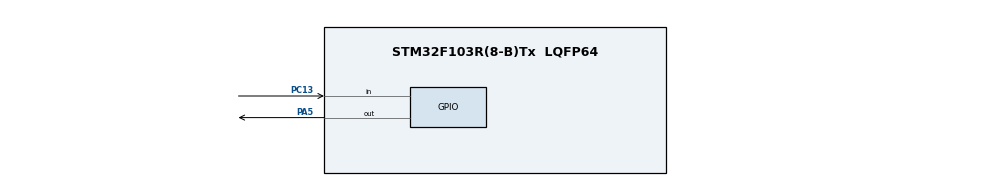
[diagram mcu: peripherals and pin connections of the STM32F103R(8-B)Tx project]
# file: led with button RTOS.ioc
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FREERTOS.Tasks01=defaultTask,24,128,StartDefaultTask,Default,NULL,Dynamic,NULL,NULL;led,24,128,ledTask02,Default,NULL,Dynamic,NULL,NULL
Mcu.Family=STM32F1
Mcu.Name=STM32F103R(8-B)Tx
Mcu.Package=LQFP64
NVIC.PriorityGroup=NVIC_PRIORITYGROUP_4
NVIC.TIM2_IRQn=true\:15\:0\:false\:false\:true\:false\:false\:true\:true
NVIC.TimeBase=TIM2_IRQn
NVIC.TimeBaseIP=TIM2
PA13.Mode=Serial_Wire
PA13.Signal=SYS_JTMS-SWDIO
PA14.Mode=Serial_Wire
PA14.Signal=SYS_JTCK-SWCLK
PA5.Signal=GPIO_Output
PC13-TAMPER-RTC.Signal=GPIO_Input
ProjectManager.HeapSize=0x200
ProjectManager.StackSize=0x400
ProjectManager.TargetToolchain=STM32CubeIDE
RCC.APB1Freq_Value=8000000
RCC.APB2Freq_Value=8000000
VP_FREERTOS_VS_CMSIS_V2.Mode=CMSIS_V2
VP_SYS_VS_tim2.Mode=TIM2
board=custom

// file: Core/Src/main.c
/* USER CODE BEGIN Header */
/**
  ******************************************************************************
  * @file           : main.c
  * @brief          : Main program body
  ******************************************************************************
  * @attention
  *
  * Copyright (c) 2026 STMicroelectronics.
  * All rights reserved.
  *
  * This software is licensed under terms that can be found in the LICENSE file
  * in the root directory of this software component.
  * If no LICENSE file comes with this software, it is provided AS-IS.
  *
  ******************************************************************************
  */
/* USER CODE END Header */
#include "main.h"
#include "cmsis_os.h"

/* Definitions for defaultTask */
osThreadId_t defaultTaskHandle;
const osThreadAttr_t defaultTask_attributes = {
  .name = "defaultTask",
  .stack_size = 128 * 4,
  .priority = (osPriority_t) osPriorityNormal,
};
/* Definitions for led */
osThreadId_t ledHandle;
const osThreadAttr_t led_attributes = {
  .name = "led",
  .stack_size = 128 * 4,
  .priority = (osPriority_t) osPriorityNormal,
};
/* USER CODE BEGIN PV */

volatile uint8_t buttonpress = 0;

/* USER CODE END PV */

void SystemClock_Config(void);
static void MX_GPIO_Init(void);
void StartDefaultTask(void *argument);
void ledTask02(void *argument);

int main(void)
{

  /* MCU Configuration--------------------------------------------------------*/

  /* Reset of all peripherals, Initializes the Flash interface and the Systick. */
  HAL_Init();

  /* Configure the system clock */
  SystemClock_Config();

  /* Initialize all configured peripherals */
  MX_GPIO_Init();

  /* Init scheduler */
  osKernelInitialize();

  /* Create the thread(s) */
  /* creation of defaultTask */
  defaultTaskHandle = osThreadNew(StartDefaultTask, NULL, &defaultTask_attributes);

  /* creation of led */
  ledHandle = osThreadNew(ledTask02, NULL, &led_attributes);

  /* Start scheduler */
  osKernelStart();

  /* We should never get here as control is now taken by the scheduler */

  /* Infinite loop */
  while (1)
  {

  }
}

void SystemClock_Config(void)
{
  RCC_OscInitTypeDef RCC_OscInitStruct = {0};
  RCC_ClkInitTypeDef RCC_ClkInitStruct = {0};

  /** Initializes the RCC Oscillators according to the specified parameters
  * in the RCC_OscInitTypeDef structure.
  */
  RCC_OscInitStruct.OscillatorType = RCC_OSCILLATORTYPE_HSI;
  RCC_OscInitStruct.HSIState = RCC_HSI_ON;
  RCC_OscInitStruct.HSICalibrationValue = RCC_HSICALIBRATION_DEFAULT;
  RCC_OscInitStruct.PLL.PLLState = RCC_PLL_NONE;
  if (HAL_RCC_OscConfig(&RCC_OscInitStruct) != HAL_OK)
  {
    Error_Handler();
  }

  /** Initializes the CPU, AHB and APB buses clocks
  */
  RCC_ClkInitStruct.ClockType = RCC_CLOCKTYPE_HCLK|RCC_CLOCKTYPE_SYSCLK
                              |RCC_CLOCKTYPE_PCLK1|RCC_CLOCKTYPE_PCLK2;
  RCC_ClkInitStruct.SYSCLKSource = RCC_SYSCLKSOURCE_HSI;
  RCC_ClkInitStruct.AHBCLKDivider = RCC_SYSCLK_DIV1;
  RCC_ClkInitStruct.APB1CLKDivider = RCC_HCLK_DIV1;
  RCC_ClkInitStruct.APB2CLKDivider = RCC_HCLK_DIV1;

  if (HAL_RCC_ClockConfig(&RCC_ClkInitStruct, FLASH_LATENCY_0) != HAL_OK)
  {
    Error_Handler();
  }
}

static void MX_GPIO_Init(void)
{
  GPIO_InitTypeDef GPIO_InitStruct = {0};

  /* GPIO Ports Clock Enable */
  __HAL_RCC_GPIOC_CLK_ENABLE();
  __HAL_RCC_GPIOA_CLK_ENABLE();

  /*Configure GPIO pin Output Level */
  HAL_GPIO_WritePin(GPIOA, GPIO_PIN_5, GPIO_PIN_RESET);

  /*Configure GPIO pin : PC13 */
  GPIO_InitStruct.Pin = GPIO_PIN_13;
  GPIO_InitStruct.Mode = GPIO_MODE_INPUT;
  GPIO_InitStruct.Pull = GPIO_NOPULL;
  HAL_GPIO_Init(GPIOC, &GPIO_InitStruct);

  /*Configure GPIO pin : PA5 */
  GPIO_InitStruct.Pin = GPIO_PIN_5;
  GPIO_InitStruct.Mode = GPIO_MODE_OUTPUT_PP;
  GPIO_InitStruct.Pull = GPIO_NOPULL;
  GPIO_InitStruct.Speed = GPIO_SPEED_FREQ_LOW;
  HAL_GPIO_Init(GPIOA, &GPIO_InitStruct);

}

void StartDefaultTask(void *argument)
{
  /* USER CODE BEGIN 5 */
  /* Infinite loop */
  for(;;)

	      {
	          if (HAL_GPIO_ReadPin(GPIOC, GPIO_PIN_13) == GPIO_PIN_RESET)
	          {

	        	   buttonpress = 1;
	          }
	          else
	       {

	         	  buttonpress = 0;
	              }

	      }

  /* USER CODE END 5 */
}

void ledTask02(void *argument)
{
  /* USER CODE BEGIN ledTask02 */
  /* Infinite loop */
  for(;;)
  {
	  {

	      {
	          if (buttonpress == 1)
	          {
	              HAL_GPIO_WritePin(GPIOA, GPIO_PIN_5, GPIO_PIN_SET);
	          }
	        else
	              {
	         	HAL_GPIO_WritePin(GPIOA, GPIO_PIN_5, GPIO_PIN_RESET);
	          }

	      }//
	  }
  }
  /* USER CODE END ledTask02 */
}

void HAL_TIM_PeriodElapsedCallback(TIM_HandleTypeDef *htim)
{
  if (htim->Instance == TIM2)
  {
    HAL_IncTick();
  }
}

void Error_Handler(void)
{
  __disable_irq();
  while (1)
  {
  }
}
